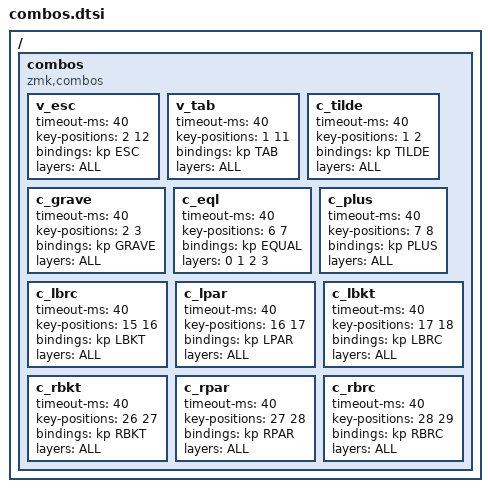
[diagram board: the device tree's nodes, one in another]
#define ALL 0 1 2 3 5 6 7 8 9
/ {
  combos {
    compatible = "zmk,combos";
    v_esc {
      timeout-ms = <40>;
      key-positions = <2 12>;
      bindings = <&kp ESC>;
      layers = <ALL>;
    };
    v_tab {
      timeout-ms = <40>;
      key-positions = <1 11>;
      bindings = <&kp TAB>;
      layers = <ALL>;
    };
    // top row
    c_tilde {
      timeout-ms = <40>;
      key-positions = <1 2>;
      bindings = <&kp TILDE>;
      layers = <ALL>;
    };
    c_grave {
      timeout-ms = <40>;
      key-positions = <2 3>;
      bindings = <&kp GRAVE>;
      layers = <ALL>;
    };
    c_eql {
      timeout-ms = <40>;
      key-positions = <6 7>;
      bindings = <&kp EQUAL>;
      layers = <0 1 2 3>;
    };
    c_plus {
      timeout-ms = <40>;
      key-positions = <7 8>;
      bindings = <&kp PLUS>;
      layers = <ALL>;
    };
    // home row [({
    c_lbrc {
      timeout-ms = <40>;
      key-positions = <15 16>;
      bindings = <&kp LBKT>;
      layers = <ALL>;
    };
    c_lpar {
      timeout-ms = <40>;
      key-positions = <16 17>;
      bindings = <&kp LPAR>;
      layers = <ALL>;
    };
    c_lbkt {
      timeout-ms = <40>;
      key-positions = <17 18>;
      bindings = <&kp LBRC>;
      layers = <ALL>;
    };
    // bottom row ])}
    c_rbkt {
      timeout-ms = <40>;
      key-positions = <26 27>;
      bindings = <&kp RBKT>;
      layers = <ALL>;
    };
    c_rpar {
      timeout-ms = <40>;
      key-positions = <27 28>;
      bindings = <&kp RPAR>;
      layers = <ALL>;
    };
    c_rbrc {
      timeout-ms = <40>;
      key-positions = <28 29>;
      bindings = <&kp RBRC>;
      layers = <ALL>;
    };
  };
};
